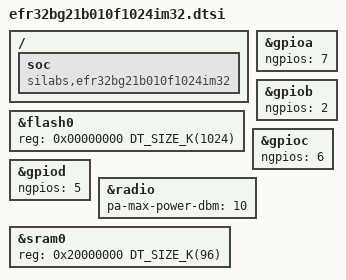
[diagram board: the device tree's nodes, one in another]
/*
 * Copyright (c) 2026 Martin Moya <martin.moya@focus.uy>
 *
 * SPDX-License-Identifier: Apache-2.0
 */

#include <mem.h>
#include <silabs/xg21/efr32bg21.dtsi>

/ {
	soc {
		compatible = "silabs,efr32bg21b010f1024im32", "silabs,efr32bg21", "silabs,xg21",
			     "silabs,efr32", "simple-bus";
	};
};

&flash0 {
	reg = <0x00000000 DT_SIZE_K(1024)>;
	ranges = <0 0x00000000 DT_SIZE_K(1024)>;
};

&gpioa {
	ngpios = <7>;
};

&gpiob {
	ngpios = <2>;
};

&gpioc {
	ngpios = <6>;
};

&gpiod {
	ngpios = <5>;
};

&radio {
	pa-max-power-dbm = <10>;
};

&sram0 {
	reg = <0x20000000 DT_SIZE_K(96)>;
};
